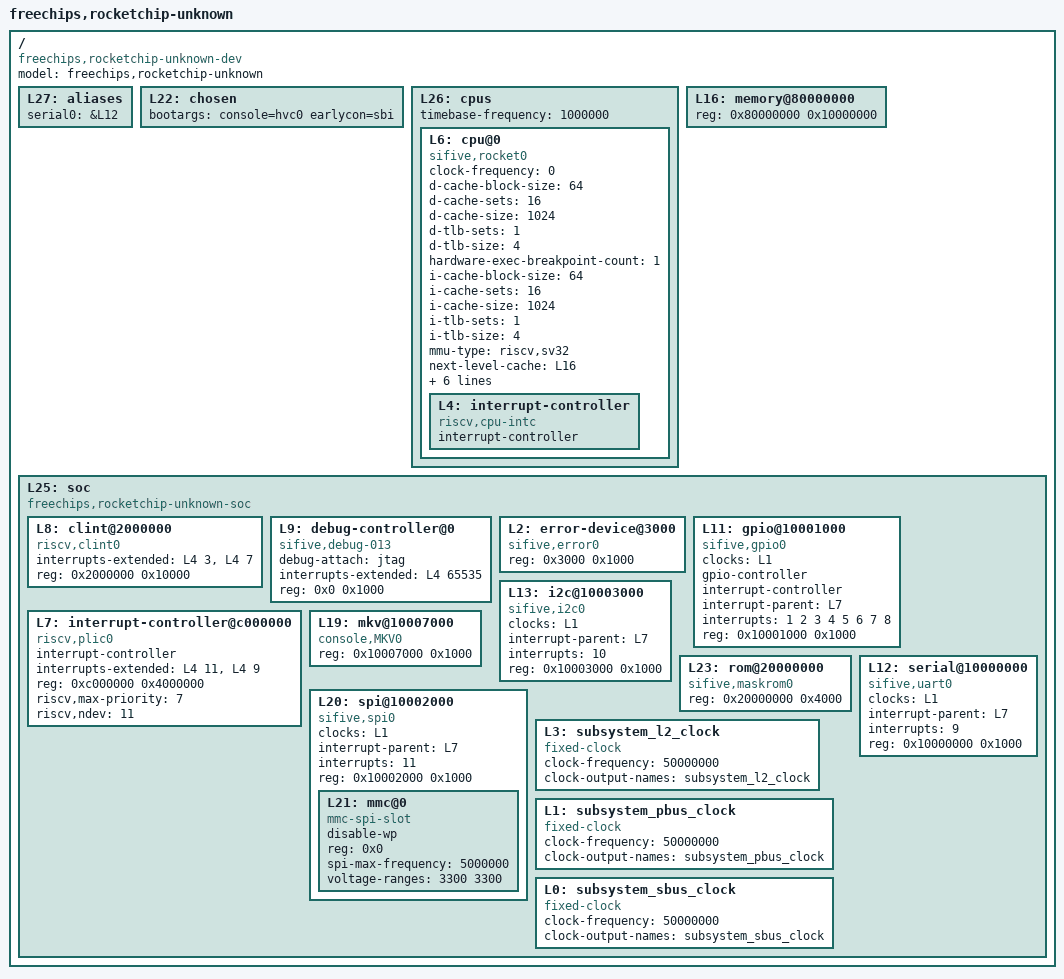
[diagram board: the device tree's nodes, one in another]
/dts-v1/;

/ {
	#address-cells = <1>;
	#size-cells = <1>;
	compatible = "freechips,rocketchip-unknown-dev";
	model = "freechips,rocketchip-unknown";
	L27: aliases {
		serial0 = &L12;
	};
	L22: chosen {
		bootargs = "console=hvc0 earlycon=sbi";
	};
	L26: cpus {
		#address-cells = <1>;
		#size-cells = <0>;
		timebase-frequency = <1000000>;
		L6: cpu@0 {
			clock-frequency = <0>;
			compatible = "sifive,rocket0", "riscv";
			d-cache-block-size = <64>;
			d-cache-sets = <16>;
			d-cache-size = <1024>;
			d-tlb-sets = <1>;
			d-tlb-size = <4>;
			device_type = "cpu";
			hardware-exec-breakpoint-count = <1>;
			i-cache-block-size = <64>;
			i-cache-sets = <16>;
			i-cache-size = <1024>;
			i-tlb-sets = <1>;
			i-tlb-size = <4>;
			mmu-type = "riscv,sv32";
			next-level-cache = <&L16>;
			reg = <0x0>;
			riscv,isa = "rv32imac";
			riscv,pmpgranularity = <4>;
			riscv,pmpregions = <8>;
			status = "okay";
			timebase-frequency = <1000000>;
			tlb-split;
			L4: interrupt-controller {
				#interrupt-cells = <1>;
				compatible = "riscv,cpu-intc";
				interrupt-controller;
			};
		};
	};
	L16: memory@80000000 {
		device_type = "memory";
		reg = <0x80000000 0x10000000>;
	};
	L25: soc {
		#address-cells = <1>;
		#size-cells = <1>;
		compatible = "freechips,rocketchip-unknown-soc", "simple-bus";
		ranges;
		L8: clint@2000000 {
			compatible = "riscv,clint0";
			interrupts-extended = <&L4 3 &L4 7>;
			reg = <0x2000000 0x10000>;
			reg-names = "control";
		};
		L9: debug-controller@0 {
			compatible = "sifive,debug-013", "riscv,debug-013";
			debug-attach = "jtag";
			interrupts-extended = <&L4 65535>;
			reg = <0x0 0x1000>;
			reg-names = "control";
		};
		L2: error-device@3000 {
			compatible = "sifive,error0";
			reg = <0x3000 0x1000>;
		};
		L11: gpio@10001000 {
			#gpio-cells = <2>;
			#interrupt-cells = <2>;
			clocks = <&L1>;
			compatible = "sifive,gpio0", "sifive,gpio1";
			gpio-controller;
			interrupt-controller;
			interrupt-parent = <&L7>;
			interrupts = <1 2 3 4 5 6 7 8>;
			reg = <0x10001000 0x1000>;
			reg-names = "control";
		};
		L13: i2c@10003000 {
			clocks = <&L1>;
			compatible = "sifive,i2c0";
			interrupt-parent = <&L7>;
			interrupts = <10>;
			reg = <0x10003000 0x1000>;
			reg-names = "control";
		};
		L7: interrupt-controller@c000000 {
			#interrupt-cells = <1>;
			compatible = "riscv,plic0";
			interrupt-controller;
			interrupts-extended = <&L4 11 &L4 9>;
			reg = <0xc000000 0x4000000>;
			reg-names = "control";
			riscv,max-priority = <7>;
			riscv,ndev = <11>;
		};
		L19: mkv@10007000 {
			compatible = "console,MKV0";
			reg = <0x10007000 0x1000>;
			reg-names = "control";
		};
		L23: rom@20000000 {
			compatible = "sifive,maskrom0";
			reg = <0x20000000 0x4000>;
			reg-names = "mem";
		};
		L12: serial@10000000 {
			clocks = <&L1>;
			compatible = "sifive,uart0";
			interrupt-parent = <&L7>;
			interrupts = <9>;
			reg = <0x10000000 0x1000>;
			reg-names = "control";
		};
		L20: spi@10002000 {
			#address-cells = <1>;
			#size-cells = <0>;
			clocks = <&L1>;
			compatible = "sifive,spi0";
			interrupt-parent = <&L7>;
			interrupts = <11>;
			reg = <0x10002000 0x1000>;
			reg-names = "control";
			L21: mmc@0 {
				compatible = "mmc-spi-slot";
				disable-wp;
				reg = <0x0>;
				spi-max-frequency = <5000000>;
				voltage-ranges = <3300 3300>;
			};
		};
		L3: subsystem_l2_clock {
			#clock-cells = <0>;
			clock-frequency = <50000000>;
			clock-output-names = "subsystem_l2_clock";
			compatible = "fixed-clock";
		};
		L1: subsystem_pbus_clock {
			#clock-cells = <0>;
			clock-frequency = <50000000>;
			clock-output-names = "subsystem_pbus_clock";
			compatible = "fixed-clock";
		};
		L0: subsystem_sbus_clock {
			#clock-cells = <0>;
			clock-frequency = <50000000>;
			clock-output-names = "subsystem_sbus_clock";
			compatible = "fixed-clock";
		};
	};
};
